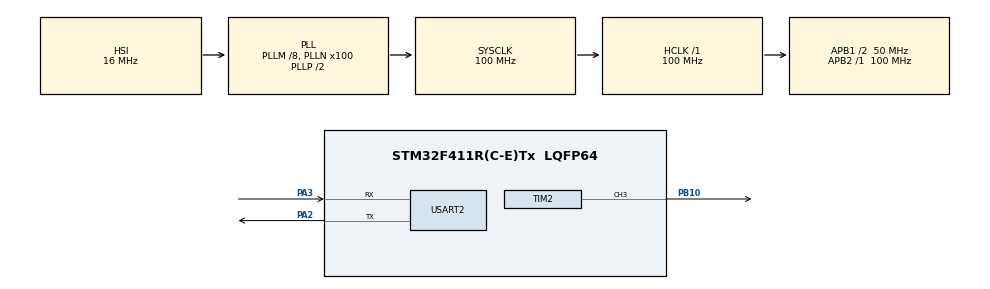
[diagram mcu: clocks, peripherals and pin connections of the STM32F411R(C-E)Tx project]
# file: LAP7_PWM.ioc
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Mcu.Family=STM32F4
Mcu.Name=STM32F411R(C-E)Tx
Mcu.Package=LQFP64
NVIC.PriorityGroup=NVIC_PRIORITYGROUP_0
PA2.Mode=Asynchronous
PA2.Signal=USART2_TX
PA3.Mode=Asynchronous
PA3.Signal=USART2_RX
PB10.GPIO_Speed=GPIO_SPEED_FREQ_VERY_HIGH
PB10.Signal=S_TIM2_CH3
ProjectManager.HeapSize=0x200
ProjectManager.StackSize=0x400
ProjectManager.TargetToolchain=MDK-ARM V5.27
RCC.48MHZClocksFreq_Value=50000000
RCC.AHBFreq_Value=100000000
RCC.APB1CLKDivider=RCC_HCLK_DIV2
RCC.APB1Freq_Value=50000000
RCC.APB1TimFreq_Value=100000000
RCC.APB2Freq_Value=100000000
RCC.APB2TimFreq_Value=100000000
RCC.CortexFreq_Value=100000000
RCC.FLatency-AdvancedSettings=FLASH_LATENCY_3
RCC.HCLKFreq_Value=100000000
RCC.HSE_VALUE=8000000
RCC.HSI_VALUE=16000000
RCC.LSE_VALUE=32768
RCC.PLLM=8
RCC.PLLN=100
RCC.SYSCLKFreq_VALUE=100000000
RCC.SYSCLKSource=RCC_SYSCLKSOURCE_PLLCLK
RCC.VCOOutputFreq_Value=200000000
SH.S_TIM2_CH3.0=TIM2_CH3,PWM Generation3 CH3
TIM2.Channel-PWM\ Generation3\ CH3=TIM_CHANNEL_3
TIM2.Period=10000-1
TIM2.Prescaler=10000-1
TIM2.Pulse-PWM\ Generation3\ CH3=(10000-1)/4
USART2.VirtualMode=VM_ASYNC
VP_TIM2_VS_ClockSourceINT.Mode=Internal
board=NUCLEO-F411RE

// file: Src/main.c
/* USER CODE BEGIN Header */
/**
  ******************************************************************************
  * @file           : main.c
  * @brief          : Main program body
  ******************************************************************************
  * @attention
  *
  * <h2><center>&copy; Copyright (c) 2020 STMicroelectronics.
  * All rights reserved.</center></h2>
  *
  * This software component is licensed by ST under BSD 3-Clause license,
  * the "License"; You may not use this file except in compliance with the
  * License. You may obtain a copy of the License at:
  *                        opensource.org/licenses/BSD-3-Clause
  *
  ******************************************************************************
  */
/* USER CODE END Header */

#include "main.h"
#include "tim.h"
#include "usart.h"
#include "gpio.h"

/* USER CODE BEGIN PV */
uint8_t pwm;
float dutyCycle = 0.8;
/* USER CODE END PV */

void SystemClock_Config(void);

int main(void)
{

  /* MCU Configuration--------------------------------------------------------*/

  /* Reset of all peripherals, Initializes the Flash interface and the Systick. */
  HAL_Init();

  /* Configure the system clock */
  SystemClock_Config();

  /* Initialize all configured peripherals */
  MX_GPIO_Init();
  MX_USART2_UART_Init();
  MX_TIM2_Init();

  /* Infinite loop */
  while (1)
  {

    /* USER CODE BEGIN 3 */
		htim2.Instance -> CCR3 = (10000-1) * dutyCycle;
		HAL_TIM_PWM_Start(&htim2, TIM_CHANNEL_3);
		HAL_Delay(1000);
		HAL_TIM_PWM_Stop(&htim2, TIM_CHANNEL_3);
		pwm = (GPIOB->IDR&0x400U)>>10;
  }
  /* USER CODE END 3 */
}

void SystemClock_Config(void)
{
  RCC_OscInitTypeDef RCC_OscInitStruct = {0};
  RCC_ClkInitTypeDef RCC_ClkInitStruct = {0};

  /** Configure the main internal regulator output voltage
  */
  __HAL_RCC_PWR_CLK_ENABLE();
  __HAL_PWR_VOLTAGESCALING_CONFIG(PWR_REGULATOR_VOLTAGE_SCALE1);
  /** Initializes the CPU, AHB and APB busses clocks
  */
  RCC_OscInitStruct.OscillatorType = RCC_OSCILLATORTYPE_HSI;
  RCC_OscInitStruct.HSIState = RCC_HSI_ON;
  RCC_OscInitStruct.HSICalibrationValue = RCC_HSICALIBRATION_DEFAULT;
  RCC_OscInitStruct.PLL.PLLState = RCC_PLL_ON;
  RCC_OscInitStruct.PLL.PLLSource = RCC_PLLSOURCE_HSI;
  RCC_OscInitStruct.PLL.PLLM = 8;
  RCC_OscInitStruct.PLL.PLLN = 100;
  RCC_OscInitStruct.PLL.PLLP = RCC_PLLP_DIV2;
  RCC_OscInitStruct.PLL.PLLQ = 4;
  if (HAL_RCC_OscConfig(&RCC_OscInitStruct) != HAL_OK)
  {
    Error_Handler();
  }
  /** Initializes the CPU, AHB and APB busses clocks
  */
  RCC_ClkInitStruct.ClockType = RCC_CLOCKTYPE_HCLK|RCC_CLOCKTYPE_SYSCLK
                              |RCC_CLOCKTYPE_PCLK1|RCC_CLOCKTYPE_PCLK2;
  RCC_ClkInitStruct.SYSCLKSource = RCC_SYSCLKSOURCE_PLLCLK;
  RCC_ClkInitStruct.AHBCLKDivider = RCC_SYSCLK_DIV1;
  RCC_ClkInitStruct.APB1CLKDivider = RCC_HCLK_DIV2;
  RCC_ClkInitStruct.APB2CLKDivider = RCC_HCLK_DIV1;

  if (HAL_RCC_ClockConfig(&RCC_ClkInitStruct, FLASH_LATENCY_3) != HAL_OK)
  {
    Error_Handler();
  }
}

void Error_Handler(void)
{
}

/************************ (C) COPYRIGHT STMicroelectronics *****END OF FILE****/
